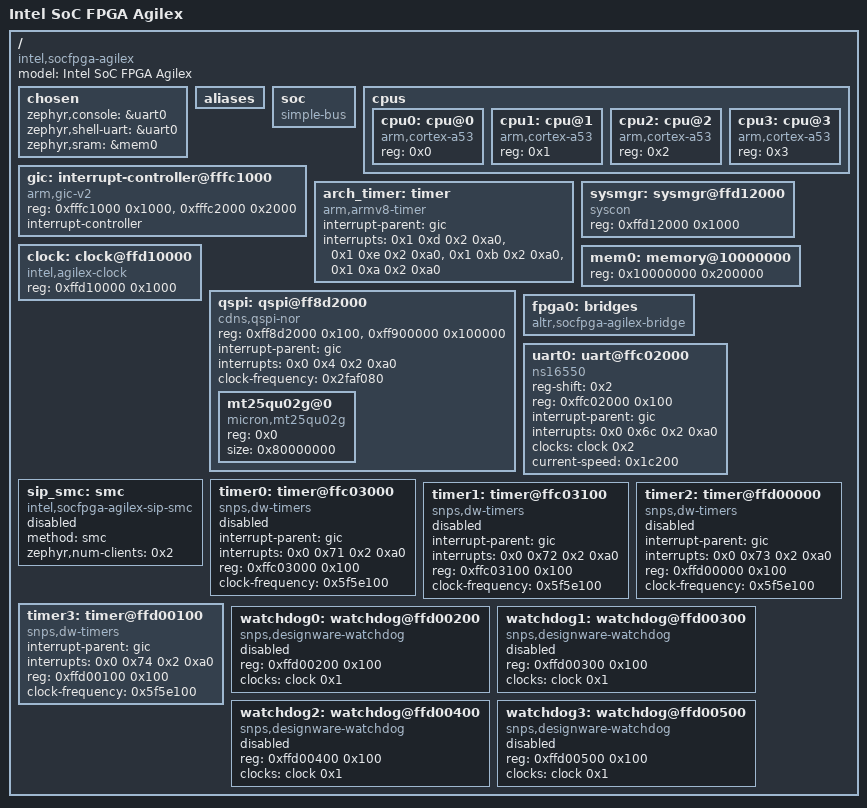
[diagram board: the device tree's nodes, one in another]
/dts-v1/;

/* node '/' defined in zephyr/dts/common/skeleton.dtsi:9 */
/ {
	model = "Intel SoC FPGA Agilex";     /* in zephyr/boards/intel/socfpga/agilex_socdk/intel_socfpga_agilex_socdk.dts:13 */
	compatible = "intel,socfpga-agilex"; /* in zephyr/boards/intel/socfpga/agilex_socdk/intel_socfpga_agilex_socdk.dts:14 */
	#address-cells = < 0x1 >;            /* in zephyr/boards/intel/socfpga/agilex_socdk/intel_socfpga_agilex_socdk.dts:15 */
	#size-cells = < 0x1 >;               /* in zephyr/boards/intel/socfpga/agilex_socdk/intel_socfpga_agilex_socdk.dts:16 */

	/* node '/chosen' defined in zephyr/dts/common/skeleton.dtsi:13 */
	chosen {
		zephyr,console = &uart0;    /* in zephyr/boards/intel/socfpga/agilex_socdk/intel_socfpga_agilex_socdk.dts:19 */
		zephyr,shell-uart = &uart0; /* in zephyr/boards/intel/socfpga/agilex_socdk/intel_socfpga_agilex_socdk.dts:20 */
		zephyr,sram = &mem0;        /* in zephyr/boards/intel/socfpga/agilex_socdk/intel_socfpga_agilex_socdk.dts:21 */
	};

	/* node '/aliases' defined in zephyr/dts/common/skeleton.dtsi:15 */
	aliases {
	};

	/* node '/soc' defined in zephyr/dts/arm64/armv8-a.dtsi:10 */
	soc {
		#address-cells = < 0x1 >;  /* in zephyr/dts/arm64/armv8-a.dtsi:11 */
		#size-cells = < 0x1 >;     /* in zephyr/dts/arm64/armv8-a.dtsi:12 */
		compatible = "simple-bus"; /* in zephyr/dts/arm64/armv8-a.dtsi:13 */
		ranges;                    /* in zephyr/dts/arm64/armv8-a.dtsi:14 */
	};

	/* node '/cpus' defined in zephyr/dts/arm64/intel/intel_socfpga_agilex.dtsi:14 */
	cpus {
		#address-cells = < 0x1 >; /* in zephyr/dts/arm64/intel/intel_socfpga_agilex.dtsi:15 */
		#size-cells = < 0x0 >;    /* in zephyr/dts/arm64/intel/intel_socfpga_agilex.dtsi:16 */

		/* node '/cpus/cpu@0' defined in zephyr/dts/arm64/intel/intel_socfpga_agilex.dtsi:18 */
		cpu0: cpu@0 {
			device_type = "cpu";           /* in zephyr/dts/arm64/intel/intel_socfpga_agilex.dtsi:19 */
			compatible = "arm,cortex-a53"; /* in zephyr/dts/arm64/intel/intel_socfpga_agilex.dtsi:20 */
			reg = < 0x0 >;                 /* in zephyr/dts/arm64/intel/intel_socfpga_agilex.dtsi:21 */
		};

		/* node '/cpus/cpu@1' defined in zephyr/dts/arm64/intel/intel_socfpga_agilex.dtsi:24 */
		cpu1: cpu@1 {
			compatible = "arm,cortex-a53"; /* in zephyr/dts/arm64/intel/intel_socfpga_agilex.dtsi:25 */
			device_type = "cpu";           /* in zephyr/dts/arm64/intel/intel_socfpga_agilex.dtsi:26 */
			reg = < 0x1 >;                 /* in zephyr/dts/arm64/intel/intel_socfpga_agilex.dtsi:27 */
		};

		/* node '/cpus/cpu@2' defined in zephyr/dts/arm64/intel/intel_socfpga_agilex.dtsi:30 */
		cpu2: cpu@2 {
			compatible = "arm,cortex-a53"; /* in zephyr/dts/arm64/intel/intel_socfpga_agilex.dtsi:31 */
			device_type = "cpu";           /* in zephyr/dts/arm64/intel/intel_socfpga_agilex.dtsi:32 */
			reg = < 0x2 >;                 /* in zephyr/dts/arm64/intel/intel_socfpga_agilex.dtsi:33 */
		};

		/* node '/cpus/cpu@3' defined in zephyr/dts/arm64/intel/intel_socfpga_agilex.dtsi:36 */
		cpu3: cpu@3 {
			compatible = "arm,cortex-a53"; /* in zephyr/dts/arm64/intel/intel_socfpga_agilex.dtsi:37 */
			device_type = "cpu";           /* in zephyr/dts/arm64/intel/intel_socfpga_agilex.dtsi:38 */
			reg = < 0x3 >;                 /* in zephyr/dts/arm64/intel/intel_socfpga_agilex.dtsi:39 */
		};
	};

	/* node '/interrupt-controller@fffc1000' defined in zephyr/dts/arm64/intel/intel_socfpga_agilex.dtsi:43 */
	gic: interrupt-controller@fffc1000 {
		compatible = "arm,gic-v2",
		             "arm,gic";      /* in zephyr/dts/arm64/intel/intel_socfpga_agilex.dtsi:44 */
		reg = < 0xfffc1000 0x1000 >,
		      < 0xfffc2000 0x2000 >; /* in zephyr/dts/arm64/intel/intel_socfpga_agilex.dtsi:45 */
		interrupt-controller;        /* in zephyr/dts/arm64/intel/intel_socfpga_agilex.dtsi:47 */
		#interrupt-cells = < 0x4 >;  /* in zephyr/dts/arm64/intel/intel_socfpga_agilex.dtsi:48 */
		status = "okay";             /* in zephyr/dts/arm64/intel/intel_socfpga_agilex.dtsi:49 */
		phandle = < 0x1 >;           /* in zephyr/dts/arm64/intel/intel_socfpga_agilex.dtsi:54 */
	};

	/* node '/timer' defined in zephyr/dts/arm64/intel/intel_socfpga_agilex.dtsi:52 */
	arch_timer: timer {
		compatible = "arm,armv8-timer";    /* in zephyr/dts/arm64/intel/intel_socfpga_agilex.dtsi:53 */
		interrupt-parent = < &gic >;       /* in zephyr/dts/arm64/intel/intel_socfpga_agilex.dtsi:54 */
		interrupts = < 0x1 0xd 0x2 0xa0 >,
		             < 0x1 0xe 0x2 0xa0 >,
		             < 0x1 0xb 0x2 0xa0 >,
		             < 0x1 0xa 0x2 0xa0 >; /* in zephyr/dts/arm64/intel/intel_socfpga_agilex.dtsi:55 */
	};

	/* node '/sysmgr@ffd12000' defined in zephyr/dts/arm64/intel/intel_socfpga_agilex.dtsi:65 */
	sysmgr: sysmgr@ffd12000 {
		compatible = "syscon";       /* in zephyr/dts/arm64/intel/intel_socfpga_agilex.dtsi:66 */
		reg = < 0xffd12000 0x1000 >; /* in zephyr/dts/arm64/intel/intel_socfpga_agilex.dtsi:67 */
	};

	/* node '/clock@ffd10000' defined in zephyr/dts/arm64/intel/intel_socfpga_agilex.dtsi:70 */
	clock: clock@ffd10000 {
		compatible = "intel,agilex-clock"; /* in zephyr/dts/arm64/intel/intel_socfpga_agilex.dtsi:71 */
		reg = < 0xffd10000 0x1000 >;       /* in zephyr/dts/arm64/intel/intel_socfpga_agilex.dtsi:72 */
		#clock-cells = < 0x1 >;            /* in zephyr/dts/arm64/intel/intel_socfpga_agilex.dtsi:73 */
		phandle = < 0x2 >;                 /* in zephyr/dts/arm64/intel/intel_socfpga_agilex.dtsi:114 */
	};

	/* node '/qspi@ff8d2000' defined in zephyr/dts/arm64/intel/intel_socfpga_agilex.dtsi:83 */
	qspi: qspi@ff8d2000 {
		#address-cells = < 0x1 >;          /* in zephyr/dts/arm64/intel/intel_socfpga_agilex.dtsi:84 */
		#size-cells = < 0x0 >;             /* in zephyr/dts/arm64/intel/intel_socfpga_agilex.dtsi:85 */
		compatible = "cdns,qspi-nor";      /* in zephyr/dts/arm64/intel/intel_socfpga_agilex.dtsi:86 */
		reg = < 0xff8d2000 0x100 >,
		      < 0xff900000 0x100000 >;     /* in zephyr/dts/arm64/intel/intel_socfpga_agilex.dtsi:87 */
		reg-names = "qspi_reg",
		            "qspi_data";           /* in zephyr/dts/arm64/intel/intel_socfpga_agilex.dtsi:89 */
		interrupt-parent = < &gic >;       /* in zephyr/dts/arm64/intel/intel_socfpga_agilex.dtsi:90 */
		interrupts = < 0x0 0x4 0x2 0xa0 >; /* in zephyr/dts/arm64/intel/intel_socfpga_agilex.dtsi:91 */
		clock-frequency = < 0x2faf080 >;   /* in zephyr/dts/arm64/intel/intel_socfpga_agilex.dtsi:93 */
		status = "okay";                   /* in zephyr/boards/intel/socfpga/agilex_socdk/intel_socfpga_agilex_socdk.dts:31 */

		/* node '/qspi@ff8d2000/mt25qu02g@0' defined in zephyr/boards/intel/socfpga/agilex_socdk/intel_socfpga_agilex_socdk.dts:33 */
		mt25qu02g@0 {
			compatible = "micron,mt25qu02g"; /* in zephyr/boards/intel/socfpga/agilex_socdk/intel_socfpga_agilex_socdk.dts:34 */
			reg = < 0x0 >;                   /* in zephyr/boards/intel/socfpga/agilex_socdk/intel_socfpga_agilex_socdk.dts:35 */
			size = < 0x80000000 >;           /* in zephyr/boards/intel/socfpga/agilex_socdk/intel_socfpga_agilex_socdk.dts:36 */
			status = "okay";                 /* in zephyr/boards/intel/socfpga/agilex_socdk/intel_socfpga_agilex_socdk.dts:37 */
		};
	};

	/* node '/memory@10000000' defined in zephyr/dts/arm64/intel/intel_socfpga_agilex.dtsi:97 */
	mem0: memory@10000000 {
		device_type = "memory";        /* in zephyr/dts/arm64/intel/intel_socfpga_agilex.dtsi:98 */
		reg = < 0x10000000 0x200000 >; /* in zephyr/dts/arm64/intel/intel_socfpga_agilex.dtsi:99 */
	};

	/* node '/bridges' defined in zephyr/dts/arm64/intel/intel_socfpga_agilex.dtsi:102 */
	fpga0: bridges {
		compatible = "altr,socfpga-agilex-bridge"; /* in zephyr/dts/arm64/intel/intel_socfpga_agilex.dtsi:103 */
	};

	/* node '/uart@ffc02000' defined in zephyr/dts/arm64/intel/intel_socfpga_agilex.dtsi:106 */
	uart0: uart@ffc02000 {
		compatible = "ns16550";             /* in zephyr/dts/arm64/intel/intel_socfpga_agilex.dtsi:107 */
		reg-shift = < 0x2 >;                /* in zephyr/dts/arm64/intel/intel_socfpga_agilex.dtsi:108 */
		reg = < 0xffc02000 0x100 >;         /* in zephyr/dts/arm64/intel/intel_socfpga_agilex.dtsi:109 */
		interrupt-parent = < &gic >;        /* in zephyr/dts/arm64/intel/intel_socfpga_agilex.dtsi:110 */
		interrupts = < 0x0 0x6c 0x2 0xa0 >; /* in zephyr/dts/arm64/intel/intel_socfpga_agilex.dtsi:111 */
		interrupt-names = "irq_0";          /* in zephyr/dts/arm64/intel/intel_socfpga_agilex.dtsi:113 */
		clocks = < &clock 0x2 >;            /* in zephyr/dts/arm64/intel/intel_socfpga_agilex.dtsi:114 */
		status = "okay";                    /* in zephyr/boards/intel/socfpga/agilex_socdk/intel_socfpga_agilex_socdk.dts:26 */
		current-speed = < 0x1c200 >;        /* in zephyr/boards/intel/socfpga/agilex_socdk/intel_socfpga_agilex_socdk.dts:27 */
	};

	/* node '/smc' defined in zephyr/dts/arm64/intel/intel_socfpga_agilex.dtsi:118 */
	sip_smc: smc {
		compatible = "intel,socfpga-agilex-sip-smc"; /* in zephyr/dts/arm64/intel/intel_socfpga_agilex.dtsi:119 */
		method = "smc";                              /* in zephyr/dts/arm64/intel/intel_socfpga_agilex.dtsi:120 */
		status = "disabled";                         /* in zephyr/dts/arm64/intel/intel_socfpga_agilex.dtsi:121 */
		zephyr,num-clients = < 0x2 >;                /* in zephyr/dts/arm64/intel/intel_socfpga_agilex.dtsi:122 */
	};

	/* node '/timer@ffc03000' defined in zephyr/dts/arm64/intel/intel_socfpga_agilex.dtsi:125 */
	timer0: timer@ffc03000 {
		compatible = "snps,dw-timers";      /* in zephyr/dts/arm64/intel/intel_socfpga_agilex.dtsi:126 */
		interrupt-parent = < &gic >;        /* in zephyr/dts/arm64/intel/intel_socfpga_agilex.dtsi:127 */
		interrupts = < 0x0 0x71 0x2 0xa0 >; /* in zephyr/dts/arm64/intel/intel_socfpga_agilex.dtsi:128 */
		reg = < 0xffc03000 0x100 >;         /* in zephyr/dts/arm64/intel/intel_socfpga_agilex.dtsi:130 */
		clock-frequency = < 0x5f5e100 >;    /* in zephyr/dts/arm64/intel/intel_socfpga_agilex.dtsi:131 */
		status = "disabled";                /* in zephyr/dts/arm64/intel/intel_socfpga_agilex.dtsi:132 */
	};

	/* node '/timer@ffc03100' defined in zephyr/dts/arm64/intel/intel_socfpga_agilex.dtsi:135 */
	timer1: timer@ffc03100 {
		compatible = "snps,dw-timers";      /* in zephyr/dts/arm64/intel/intel_socfpga_agilex.dtsi:136 */
		interrupt-parent = < &gic >;        /* in zephyr/dts/arm64/intel/intel_socfpga_agilex.dtsi:137 */
		interrupts = < 0x0 0x72 0x2 0xa0 >; /* in zephyr/dts/arm64/intel/intel_socfpga_agilex.dtsi:138 */
		reg = < 0xffc03100 0x100 >;         /* in zephyr/dts/arm64/intel/intel_socfpga_agilex.dtsi:140 */
		clock-frequency = < 0x5f5e100 >;    /* in zephyr/dts/arm64/intel/intel_socfpga_agilex.dtsi:141 */
		status = "disabled";                /* in zephyr/dts/arm64/intel/intel_socfpga_agilex.dtsi:142 */
	};

	/* node '/timer@ffd00000' defined in zephyr/dts/arm64/intel/intel_socfpga_agilex.dtsi:145 */
	timer2: timer@ffd00000 {
		compatible = "snps,dw-timers";      /* in zephyr/dts/arm64/intel/intel_socfpga_agilex.dtsi:146 */
		interrupt-parent = < &gic >;        /* in zephyr/dts/arm64/intel/intel_socfpga_agilex.dtsi:147 */
		interrupts = < 0x0 0x73 0x2 0xa0 >; /* in zephyr/dts/arm64/intel/intel_socfpga_agilex.dtsi:148 */
		reg = < 0xffd00000 0x100 >;         /* in zephyr/dts/arm64/intel/intel_socfpga_agilex.dtsi:150 */
		clock-frequency = < 0x5f5e100 >;    /* in zephyr/dts/arm64/intel/intel_socfpga_agilex.dtsi:151 */
		status = "disabled";                /* in zephyr/dts/arm64/intel/intel_socfpga_agilex.dtsi:152 */
	};

	/* node '/timer@ffd00100' defined in zephyr/dts/arm64/intel/intel_socfpga_agilex.dtsi:155 */
	timer3: timer@ffd00100 {
		compatible = "snps,dw-timers";      /* in zephyr/dts/arm64/intel/intel_socfpga_agilex.dtsi:156 */
		interrupt-parent = < &gic >;        /* in zephyr/dts/arm64/intel/intel_socfpga_agilex.dtsi:157 */
		interrupts = < 0x0 0x74 0x2 0xa0 >; /* in zephyr/dts/arm64/intel/intel_socfpga_agilex.dtsi:158 */
		reg = < 0xffd00100 0x100 >;         /* in zephyr/dts/arm64/intel/intel_socfpga_agilex.dtsi:160 */
		clock-frequency = < 0x5f5e100 >;    /* in zephyr/dts/arm64/intel/intel_socfpga_agilex.dtsi:161 */
	};

	/* node '/watchdog@ffd00200' defined in zephyr/dts/arm64/intel/intel_socfpga_agilex.dtsi:164 */
	watchdog0: watchdog@ffd00200 {
		compatible = "snps,designware-watchdog"; /* in zephyr/dts/arm64/intel/intel_socfpga_agilex.dtsi:165 */
		reg = < 0xffd00200 0x100 >;              /* in zephyr/dts/arm64/intel/intel_socfpga_agilex.dtsi:166 */
		clocks = < &clock 0x1 >;                 /* in zephyr/dts/arm64/intel/intel_socfpga_agilex.dtsi:167 */
		status = "disabled";                     /* in zephyr/dts/arm64/intel/intel_socfpga_agilex.dtsi:168 */
	};

	/* node '/watchdog@ffd00300' defined in zephyr/dts/arm64/intel/intel_socfpga_agilex.dtsi:171 */
	watchdog1: watchdog@ffd00300 {
		compatible = "snps,designware-watchdog"; /* in zephyr/dts/arm64/intel/intel_socfpga_agilex.dtsi:172 */
		reg = < 0xffd00300 0x100 >;              /* in zephyr/dts/arm64/intel/intel_socfpga_agilex.dtsi:173 */
		clocks = < &clock 0x1 >;                 /* in zephyr/dts/arm64/intel/intel_socfpga_agilex.dtsi:174 */
		status = "disabled";                     /* in zephyr/dts/arm64/intel/intel_socfpga_agilex.dtsi:175 */
	};

	/* node '/watchdog@ffd00400' defined in zephyr/dts/arm64/intel/intel_socfpga_agilex.dtsi:178 */
	watchdog2: watchdog@ffd00400 {
		compatible = "snps,designware-watchdog"; /* in zephyr/dts/arm64/intel/intel_socfpga_agilex.dtsi:179 */
		reg = < 0xffd00400 0x100 >;              /* in zephyr/dts/arm64/intel/intel_socfpga_agilex.dtsi:180 */
		clocks = < &clock 0x1 >;                 /* in zephyr/dts/arm64/intel/intel_socfpga_agilex.dtsi:181 */
		status = "disabled";                     /* in zephyr/dts/arm64/intel/intel_socfpga_agilex.dtsi:182 */
	};

	/* node '/watchdog@ffd00500' defined in zephyr/dts/arm64/intel/intel_socfpga_agilex.dtsi:185 */
	watchdog3: watchdog@ffd00500 {
		compatible = "snps,designware-watchdog"; /* in zephyr/dts/arm64/intel/intel_socfpga_agilex.dtsi:186 */
		reg = < 0xffd00500 0x100 >;              /* in zephyr/dts/arm64/intel/intel_socfpga_agilex.dtsi:187 */
		clocks = < &clock 0x1 >;                 /* in zephyr/dts/arm64/intel/intel_socfpga_agilex.dtsi:188 */
		status = "disabled";                     /* in zephyr/dts/arm64/intel/intel_socfpga_agilex.dtsi:189 */
	};
};
